AUTOSAR XML (schema 4-0-3)
package /ComponentTypes
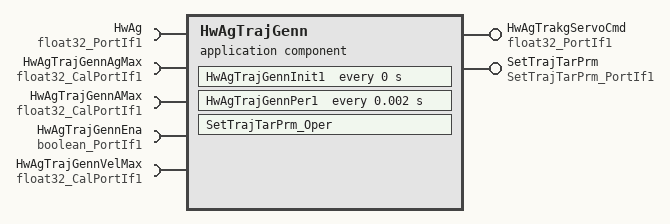
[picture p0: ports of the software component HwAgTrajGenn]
  application sw component type HwAgTrajGenn
    provide port HwAgTrakgServoCmd: nonqueued-sender-com-spec{data-element=Val, init-value=0}, provided-interface=float32_PortIf1
    provide port SetTrajTarPrm: server-com-spec{operation=Oper, queue-length=1}, provided-interface=SetTrajTarPrm_PortIf1
    5 x require port:
      HwAg: nonqueued-receiver-com-spec{data-element=Val, filter=data-filter-type=ALWAYS, init-value=0}, required-interface=float32_PortIf1
      HwAgTrajGennAgMax: parameter-require-com-spec{init-value=100, parameter=Val}, required-interface=float32_CalPortIf1
      HwAgTrajGennAMax: parameter-require-com-spec{init-value=500, parameter=Val}, required-interface=float32_CalPortIf1
      HwAgTrajGennEna: nonqueued-receiver-com-spec{data-element=Logl, filter=data-filter-type=ALWAYS, init-value=0}, required-interface=boolean_PortIf1
      HwAgTrajGennVelMax: parameter-require-com-spec{init-value=50, parameter=Val}, required-interface=float32_CalPortIf1
    behavior HwAgTrajGenn_InternalBehavior
      ar-typed-per-instance-memorys:
        10 x data, all with sw-calibration-access=READ-ONLY:
          AMax: type=float32
          CalcFlg: type=boolean
          CmdSt: type=HwAgTrajCmdSt1
          HwPosnIni: type=float32
          HwPosnOffs: type=float32
          SignHwPosnDelta: type=float32
          TiDeltaA: type=float32
          TiDeltaVel: type=float32
          TiSt: type=float32
          VelMax: type=float32
      timing event HwAgTrajGennInit1_InitEvent: start-on-event=HwAgTrajGennInit1, period=0
      timing event TMT_HwAgTrajGennPer1: start-on-event=HwAgTrajGennPer1, period=0.002
      operation invoked event OIT_SetTrajTarPrm_Oper_SetTrajTarPrm_Oper: start-on-event=SetTrajTarPrm_Oper, operation=SetTrajTarPrm.Oper
      explicit-inter-runnable-variables:
        data HwAgTar: type=float32, init-value=0
        data HwATar: type=float32, init-value=10
        data HwVelTar: type=float32, init-value=10
      runnable HwAgTrajGennInit1
      runnable HwAgTrajGennPer1
        data-receive-point-by-arguments:
          access REC_HwAg_Val: accessed-variable=HwAg.Val
          access REC_HwAgTrajGennEna_Logl: accessed-variable=HwAgTrajGennEna.Logl
        data-send-points:
          access SEND_HwAgTrakgServoCmd_Val: accessed-variable=HwAgTrakgServoCmd.Val
        read-local-variables:
          access READ_HwATar: accessed-variable=HwATar
          access READ_HwAgTar: accessed-variable=HwAgTar
          access READ_HwVelTar: accessed-variable=HwVelTar
      runnable SetTrajTarPrm_Oper
        written-local-variables:
          access WRITE_HwATar: accessed-variable=HwATar
          access WRITE_HwAgTar: accessed-variable=HwAgTar
          access WRITE_HwVelTar: accessed-variable=HwVelTar
  swc implementation HwAgTrajGenn_Implementation: behavior=HwAgTrajGenn_InternalBehavior
    code-descriptors:
      code Default: artifact-descriptors=autosar-engineering-object={short-label=Default, category=SWSRC}
